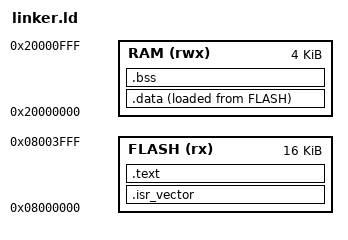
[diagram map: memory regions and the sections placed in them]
MEMORY
{
  FLASH (rx) : ORIGIN = 0x08000000, LENGTH = 16K
  RAM (rwx)  : ORIGIN = 0x20000000, LENGTH = 4K
}

ENTRY(Reset_Handler)

SECTIONS
{
  .isr_vector :
  {
    KEEP(*(.isr_vector))
  } > FLASH

  .text :
  {
    *(.text*)
    *(.rodata*)
  } > FLASH

  .data :
  {
    *(.data*)
  } > RAM AT > FLASH

  .bss :
  {
    *(.bss*)
    *(COMMON)
  } > RAM
}
